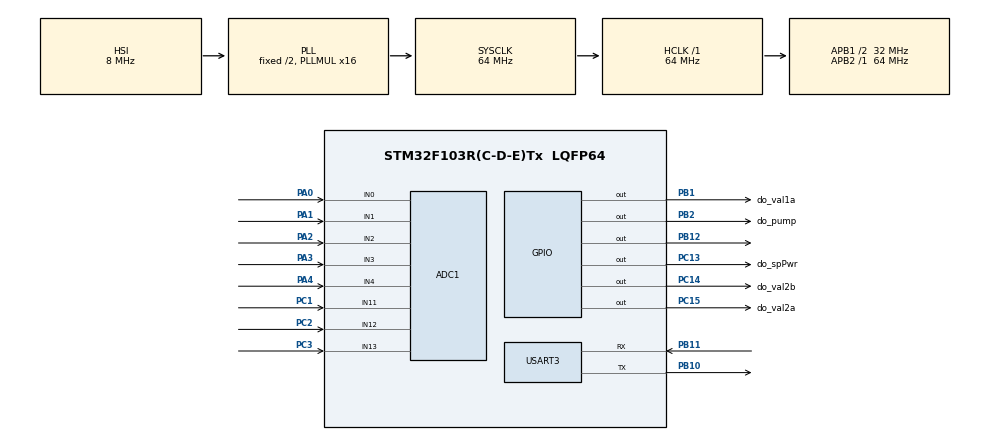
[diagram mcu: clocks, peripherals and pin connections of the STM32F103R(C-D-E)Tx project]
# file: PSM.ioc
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ADC1.Channel-0\#ChannelRegularConversion=ADC_CHANNEL_0
ADC1.Channel-1\#ChannelRegularConversion=ADC_CHANNEL_1
ADC1.Channel-2\#ChannelRegularConversion=ADC_CHANNEL_2
ADC1.Channel-3\#ChannelRegularConversion=ADC_CHANNEL_3
ADC1.Channel-4\#ChannelRegularConversion=ADC_CHANNEL_4
ADC1.Channel-5\#ChannelRegularConversion=ADC_CHANNEL_11
ADC1.Channel-6\#ChannelRegularConversion=ADC_CHANNEL_12
ADC1.Channel-7\#ChannelRegularConversion=ADC_CHANNEL_13
ADC1.ContinuousConvMode=ENABLE
ADC1.NbrOfConversion=8
ADC1.NbrOfConversionFlag=1
ADC1.Rank-0\#ChannelRegularConversion=1
ADC1.Rank-1\#ChannelRegularConversion=2
ADC1.Rank-2\#ChannelRegularConversion=3
ADC1.Rank-3\#ChannelRegularConversion=4
ADC1.Rank-4\#ChannelRegularConversion=5
ADC1.Rank-5\#ChannelRegularConversion=6
ADC1.Rank-6\#ChannelRegularConversion=7
ADC1.Rank-7\#ChannelRegularConversion=8
ADC1.SamplingTime-0\#ChannelRegularConversion=ADC_SAMPLETIME_71CYCLES_5
ADC1.SamplingTime-1\#ChannelRegularConversion=ADC_SAMPLETIME_71CYCLES_5
ADC1.SamplingTime-2\#ChannelRegularConversion=ADC_SAMPLETIME_71CYCLES_5
ADC1.SamplingTime-3\#ChannelRegularConversion=ADC_SAMPLETIME_71CYCLES_5
ADC1.SamplingTime-4\#ChannelRegularConversion=ADC_SAMPLETIME_71CYCLES_5
ADC1.SamplingTime-5\#ChannelRegularConversion=ADC_SAMPLETIME_71CYCLES_5
ADC1.SamplingTime-6\#ChannelRegularConversion=ADC_SAMPLETIME_71CYCLES_5
ADC1.SamplingTime-7\#ChannelRegularConversion=ADC_SAMPLETIME_71CYCLES_5
ADC1.master=1
Dma.ADC1.0.Direction=DMA_PERIPH_TO_MEMORY
Dma.ADC1.0.Instance=DMA1_Channel1
Dma.ADC1.0.MemDataAlignment=DMA_MDATAALIGN_HALFWORD
Dma.ADC1.0.MemInc=DMA_MINC_ENABLE
Dma.ADC1.0.Mode=DMA_CIRCULAR
Dma.ADC1.0.PeriphDataAlignment=DMA_PDATAALIGN_HALFWORD
Dma.ADC1.0.PeriphInc=DMA_PINC_DISABLE
Dma.ADC1.0.Priority=DMA_PRIORITY_LOW
Dma.Request0=ADC1
Mcu.Family=STM32F1
Mcu.Name=STM32F103R(C-D-E)Tx
Mcu.Package=LQFP64
NVIC.DMA1_Channel1_IRQn=true\:0\:0\:false\:false\:true\:false\:true\:true
NVIC.PriorityGroup=NVIC_PRIORITYGROUP_4
PA0-WKUP.Signal=ADCx_IN0
PA1.Signal=ADCx_IN1
PA13.Mode=JTAG_5_pins
PA13.Signal=SYS_JTMS-SWDIO
PA14.Mode=JTAG_5_pins
PA14.Signal=SYS_JTCK-SWCLK
PA15.Mode=JTAG_5_pins
PA15.Signal=SYS_JTDI
PA2.Signal=ADCx_IN2
PA3.Signal=ADCx_IN3
PA4.Signal=ADCx_IN4
PB1.GPIO_Label=do_val1a
PB1.Signal=GPIO_Output
PB10.Mode=Asynchronous
PB10.Signal=USART3_TX
PB11.Mode=Asynchronous
PB11.Signal=USART3_RX
PB12.Signal=GPIO_Output
PB2.GPIO_Label=do_pump
PB2.Signal=GPIO_Output
PB3.Mode=JTAG_5_pins
PB3.Signal=SYS_JTDO-TRACESWO
PB4.Mode=JTAG_5_pins
PB4.Signal=SYS_NJTRST
PC1.Signal=ADCx_IN11
PC13-TAMPER-RTC.GPIO_Label=do_spPwr
PC13-TAMPER-RTC.Signal=GPIO_Output
PC14-OSC32_IN.GPIO_Label=do_val2b
PC14-OSC32_IN.Signal=GPIO_Output
PC15-OSC32_OUT.GPIO_Label=do_val2a
PC15-OSC32_OUT.Signal=GPIO_Output
PC2.Signal=ADCx_IN12
PC3.Signal=ADCx_IN13
PD0-OSC_IN.Mode=HSE-External-Oscillator
PD0-OSC_IN.Signal=RCC_OSC_IN
PD1-OSC_OUT.Mode=HSE-External-Oscillator
PD1-OSC_OUT.Signal=RCC_OSC_OUT
ProjectManager.HeapSize=0x200
ProjectManager.StackSize=0x400
ProjectManager.TargetToolchain=STM32CubeIDE
RCC.ADCPresc=RCC_ADCPCLK2_DIV6
RCC.AHBFreq_Value=64000000
RCC.APB1CLKDivider=RCC_HCLK_DIV2
RCC.APB1Freq_Value=32000000
RCC.APB1TimFreq_Value=64000000
RCC.APB2Freq_Value=64000000
RCC.APB2TimFreq_Value=64000000
RCC.HCLKFreq_Value=64000000
RCC.PLLMUL=RCC_PLL_MUL16
RCC.SYSCLKFreq_VALUE=64000000
RCC.SYSCLKSource=RCC_SYSCLKSOURCE_PLLCLK
RCC.USBFreq_Value=64000000
SH.ADCx_IN0.0=ADC1_IN0,IN0
SH.ADCx_IN1.0=ADC1_IN1,IN1
SH.ADCx_IN11.0=ADC1_IN11,IN11
SH.ADCx_IN12.0=ADC1_IN12,IN12
SH.ADCx_IN13.0=ADC1_IN13,IN13
SH.ADCx_IN2.0=ADC1_IN2,IN2
SH.ADCx_IN3.0=ADC1_IN3,IN3
SH.ADCx_IN4.0=ADC1_IN4,IN4
USART3.VirtualMode=VM_ASYNC
board=custom

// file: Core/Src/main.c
/* USER CODE BEGIN Header */
/**
  ******************************************************************************
  * @file           : main.c
  * @brief          : Main program body
  ******************************************************************************
  * @attention
  *
  * Copyright (c) 2025 STMicroelectronics.
  * All rights reserved.
  *
  * This software is licensed under terms that can be found in the LICENSE file
  * in the root directory of this software component.
  * If no LICENSE file comes with this software, it is provided AS-IS.
  *
  ******************************************************************************
  */
/* USER CODE END Header */
#include "main.h"
#include "IOHWAB.h"
#include "Seat_StateMngr.h"
#include "KbdDrv.h"
#include "SeatPositionControl.h"

/* USER CODE BEGIN PTD */
unsigned char main1msFlag= 0;
unsigned char main10msTickTout= 0;
/* USER CODE END PTD */

ADC_HandleTypeDef hadc1;
DMA_HandleTypeDef hdma_adc1;

UART_HandleTypeDef huart3;

void SystemClock_Config(void);
static void MX_GPIO_Init(void);
static void MX_DMA_Init(void);
static void MX_ADC1_Init(void);
static void MX_USART3_UART_Init(void);
/* USER CODE BEGIN PFP */
void Task_Init(void);
/* USER CODE END PFP */

/* USER CODE BEGIN 0 */
void Task_Init(void){

	IOHWAB_Init();

	Stm_Init();

	KbdDrv_Init();

	SeatPosCtrl_Init();
}
/* USER CODE END 0 */

int main(void)
{

  /* MCU Configuration--------------------------------------------------------*/

  /* Reset of all peripherals, Initializes the Flash interface and the Systick. */
  HAL_Init();

  /* Configure the system clock */
  SystemClock_Config();

  /* Initialize all configured peripherals */
  MX_GPIO_Init();
  MX_DMA_Init();
  MX_ADC1_Init();
  MX_USART3_UART_Init();
  /* USER CODE BEGIN 2 */
  Task_Init();
  /* USER CODE END 2 */

  /* Infinite loop */
  while (1)
  {
	  if(main1msFlag!= 0){
	 	  	main1msFlag= 0;
	 	  	main10msTickTout++;
	 	  	if (main10msTickTout>= 10){
	 	  		main10msTickTout= 0;

	 	  		IOHWAB_Task();

	 	  		Stm_Task();

	 	  		KbdDrv_Task();

	 	  		SeatPosCtrl_Task();
	 	  		  }
	 	  	  }
  }
}

void SystemClock_Config(void)
{
  RCC_OscInitTypeDef RCC_OscInitStruct = {0};
  RCC_ClkInitTypeDef RCC_ClkInitStruct = {0};
  RCC_PeriphCLKInitTypeDef PeriphClkInit = {0};

  /** Initializes the RCC Oscillators according to the specified parameters
  * in the RCC_OscInitTypeDef structure.
  */
  RCC_OscInitStruct.OscillatorType = RCC_OSCILLATORTYPE_HSI;
  RCC_OscInitStruct.HSIState = RCC_HSI_ON;
  RCC_OscInitStruct.HSICalibrationValue = RCC_HSICALIBRATION_DEFAULT;
  RCC_OscInitStruct.PLL.PLLState = RCC_PLL_ON;
  RCC_OscInitStruct.PLL.PLLSource = RCC_PLLSOURCE_HSI_DIV2;
  RCC_OscInitStruct.PLL.PLLMUL = RCC_PLL_MUL16;
  if (HAL_RCC_OscConfig(&RCC_OscInitStruct) != HAL_OK)
  {
    Error_Handler();
  }

  /** Initializes the CPU, AHB and APB buses clocks
  */
  RCC_ClkInitStruct.ClockType = RCC_CLOCKTYPE_HCLK|RCC_CLOCKTYPE_SYSCLK
                              |RCC_CLOCKTYPE_PCLK1|RCC_CLOCKTYPE_PCLK2;
  RCC_ClkInitStruct.SYSCLKSource = RCC_SYSCLKSOURCE_PLLCLK;
  RCC_ClkInitStruct.AHBCLKDivider = RCC_SYSCLK_DIV1;
  RCC_ClkInitStruct.APB1CLKDivider = RCC_HCLK_DIV2;
  RCC_ClkInitStruct.APB2CLKDivider = RCC_HCLK_DIV1;

  if (HAL_RCC_ClockConfig(&RCC_ClkInitStruct, FLASH_LATENCY_2) != HAL_OK)
  {
    Error_Handler();
  }
  PeriphClkInit.PeriphClockSelection = RCC_PERIPHCLK_ADC;
  PeriphClkInit.AdcClockSelection = RCC_ADCPCLK2_DIV6;
  if (HAL_RCCEx_PeriphCLKConfig(&PeriphClkInit) != HAL_OK)
  {
    Error_Handler();
  }
}

static void MX_ADC1_Init(void)
{

  ADC_ChannelConfTypeDef sConfig = {0};

  /** Common config
  */
  hadc1.Instance = ADC1;
  hadc1.Init.ScanConvMode = ADC_SCAN_ENABLE;
  hadc1.Init.ContinuousConvMode = ENABLE;
  hadc1.Init.DiscontinuousConvMode = DISABLE;
  hadc1.Init.ExternalTrigConv = ADC_SOFTWARE_START;
  hadc1.Init.DataAlign = ADC_DATAALIGN_RIGHT;
  hadc1.Init.NbrOfConversion = 8;
  if (HAL_ADC_Init(&hadc1) != HAL_OK)
  {
    Error_Handler();
  }

  /** Configure Regular Channel
  */
  sConfig.Channel = ADC_CHANNEL_0;
  sConfig.Rank = ADC_REGULAR_RANK_1;
  sConfig.SamplingTime = ADC_SAMPLETIME_71CYCLES_5;
  if (HAL_ADC_ConfigChannel(&hadc1, &sConfig) != HAL_OK)
  {
    Error_Handler();
  }

  /** Configure Regular Channel
  */
  sConfig.Channel = ADC_CHANNEL_1;
  sConfig.Rank = ADC_REGULAR_RANK_2;
  if (HAL_ADC_ConfigChannel(&hadc1, &sConfig) != HAL_OK)
  {
    Error_Handler();
  }

  /** Configure Regular Channel
  */
  sConfig.Channel = ADC_CHANNEL_2;
  sConfig.Rank = ADC_REGULAR_RANK_3;
  if (HAL_ADC_ConfigChannel(&hadc1, &sConfig) != HAL_OK)
  {
    Error_Handler();
  }

  /** Configure Regular Channel
  */
  sConfig.Channel = ADC_CHANNEL_3;
  sConfig.Rank = ADC_REGULAR_RANK_4;
  if (HAL_ADC_ConfigChannel(&hadc1, &sConfig) != HAL_OK)
  {
    Error_Handler();
  }

  /** Configure Regular Channel
  */
  sConfig.Channel = ADC_CHANNEL_4;
  sConfig.Rank = ADC_REGULAR_RANK_5;
  if (HAL_ADC_ConfigChannel(&hadc1, &sConfig) != HAL_OK)
  {
    Error_Handler();
  }

  /** Configure Regular Channel
  */
  sConfig.Channel = ADC_CHANNEL_11;
  sConfig.Rank = ADC_REGULAR_RANK_6;
  if (HAL_ADC_ConfigChannel(&hadc1, &sConfig) != HAL_OK)
  {
    Error_Handler();
  }

  /** Configure Regular Channel
  */
  sConfig.Channel = ADC_CHANNEL_12;
  sConfig.Rank = ADC_REGULAR_RANK_7;
  if (HAL_ADC_ConfigChannel(&hadc1, &sConfig) != HAL_OK)
  {
    Error_Handler();
  }

  /** Configure Regular Channel
  */
  sConfig.Channel = ADC_CHANNEL_13;
  sConfig.Rank = ADC_REGULAR_RANK_8;
  if (HAL_ADC_ConfigChannel(&hadc1, &sConfig) != HAL_OK)
  {
    Error_Handler();
  }

}

static void MX_USART3_UART_Init(void)
{

  huart3.Instance = USART3;
  huart3.Init.BaudRate = 115200;
  huart3.Init.WordLength = UART_WORDLENGTH_8B;
  huart3.Init.StopBits = UART_STOPBITS_1;
  huart3.Init.Parity = UART_PARITY_NONE;
  huart3.Init.Mode = UART_MODE_TX_RX;
  huart3.Init.HwFlowCtl = UART_HWCONTROL_NONE;
  huart3.Init.OverSampling = UART_OVERSAMPLING_16;
  if (HAL_UART_Init(&huart3) != HAL_OK)
  {
    Error_Handler();
  }

}

static void MX_DMA_Init(void)
{

  /* DMA controller clock enable */
  __HAL_RCC_DMA1_CLK_ENABLE();

  /* DMA interrupt init */
  /* DMA1_Channel1_IRQn interrupt configuration */
  HAL_NVIC_SetPriority(DMA1_Channel1_IRQn, 0, 0);
  HAL_NVIC_EnableIRQ(DMA1_Channel1_IRQn);

}

static void MX_GPIO_Init(void)
{
  GPIO_InitTypeDef GPIO_InitStruct = {0};

  /* GPIO Ports Clock Enable */
  __HAL_RCC_GPIOC_CLK_ENABLE();
  __HAL_RCC_GPIOD_CLK_ENABLE();
  __HAL_RCC_GPIOA_CLK_ENABLE();
  __HAL_RCC_GPIOB_CLK_ENABLE();

  /*Configure GPIO pin Output Level */
  HAL_GPIO_WritePin(GPIOC, do_spPwr_Pin|do_val2b_Pin|do_val2a_Pin, GPIO_PIN_RESET);

  /*Configure GPIO pin Output Level */
  HAL_GPIO_WritePin(GPIOB, do_val1a_Pin|do_pump_Pin|GPIO_PIN_12, GPIO_PIN_RESET);

  /*Configure GPIO pins : do_spPwr_Pin do_val2b_Pin do_val2a_Pin */
  GPIO_InitStruct.Pin = do_spPwr_Pin|do_val2b_Pin|do_val2a_Pin;
  GPIO_InitStruct.Mode = GPIO_MODE_OUTPUT_PP;
  GPIO_InitStruct.Pull = GPIO_NOPULL;
  GPIO_InitStruct.Speed = GPIO_SPEED_FREQ_LOW;
  HAL_GPIO_Init(GPIOC, &GPIO_InitStruct);

  /*Configure GPIO pins : do_val1a_Pin do_pump_Pin PB12 */
  GPIO_InitStruct.Pin = do_val1a_Pin|do_pump_Pin|GPIO_PIN_12;
  GPIO_InitStruct.Mode = GPIO_MODE_OUTPUT_PP;
  GPIO_InitStruct.Pull = GPIO_NOPULL;
  GPIO_InitStruct.Speed = GPIO_SPEED_FREQ_LOW;
  HAL_GPIO_Init(GPIOB, &GPIO_InitStruct);

}

void Error_Handler(void)
{
  __disable_irq();
  while (1)
  {
  }
}
